AUTOSAR XML (schema 00049)
package /AdaptiveApplicationSwComponentTypes
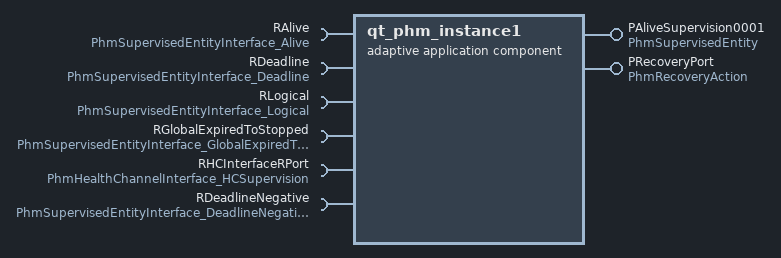
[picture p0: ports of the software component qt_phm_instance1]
  adaptive application sw component type qt_phm_instance1: category=APPLICATION_LEVEL
    provide port PAliveSupervision0001: provided-interface=PhmSupervisedEntity
    5 x require port:
      RAlive: required-interface=PhmSupervisedEntityInterface_Alive
      RDeadline: required-interface=PhmSupervisedEntityInterface_Deadline
      RLogical: required-interface=PhmSupervisedEntityInterface_Logical
      RGlobalExpiredToStopped: required-interface=PhmSupervisedEntityInterface_GlobalExpiredToStopped
      RHCInterfaceRPort: required-interface=PhmHealthChannelInterface_HCSupervision
    provide port PRecoveryPort: provided-interface=PhmRecoveryAction
    require port RDeadlineNegative: required-interface=PhmSupervisedEntityInterface_DeadlineNegative
package /Executables
  executable qt_phm_instance1
    root sw component prototype rootSwComponentPrototype: application-type=qt_phm_instance1
package /ProcessDesign
  process design qt_phm_instance1: executable=qt_phm_instance1
